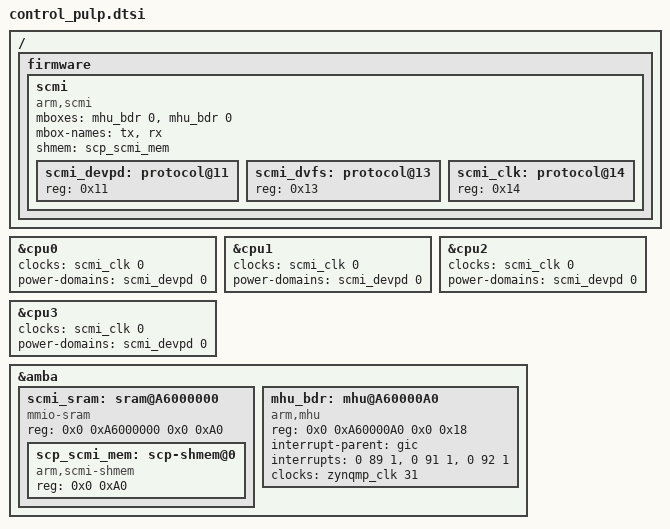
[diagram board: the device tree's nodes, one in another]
/ { //space after / is needed
    firmware{
        scmi {
            compatible ="arm,scmi";
            mboxes = <&mhu_bdr 0 &mhu_bdr 0>; 
            mbox-names = "tx","rx";
            shmem = <&scp_scmi_mem>;
            #address-cells = <1>;
            #size-cells = <0>; 

            
    		scmi_devpd: protocol@11 {
		    	reg = <0x11>;
		    	#power-domain-cells = <1>;
	    	};


            scmi_dvfs: protocol@13 {
			    reg = <0x13>;
			    #clock-cells = <1>;
		    };

            scmi_clk: protocol@14 {
			    reg = <0x14>;
			    #clock-cells = <1>;
	    	};

            // scmi_reset: protocol@16 {
			//     reg = <0x16>;
			//     #reset-cells = <1>;
	    	// };
            
            // scmi_volt: protocol@17 {
			//     reg = <0x17>;
			//     #clock-cells = <1>;
	    	// };
            
        };
    };

};//root node has to stay here (if amba is included in this node -> syntax error)

&cpu0 {
	clocks = <&scmi_clk 0>;
    power-domains = <&scmi_devpd 0>;
};

&cpu1 {
	clocks = <&scmi_clk 0>;
    power-domains = <&scmi_devpd 0>;
};

&cpu2 {
	clocks = <&scmi_clk 0>;
    power-domains = <&scmi_devpd 0>;
};

&cpu3 {
	clocks = <&scmi_clk 0>;
	power-domains = <&scmi_devpd 0>;
};

&amba{
    scmi_sram: sram@A6000000{
        compatible = "mmio-sram";
        reg = <0x0 0xA6000000 0x0 0xA0>; 
        #address-cells = <1>;
        #size-cells = <1>;
        ranges = <0 0x0 0xA6000000 0xA0>; 

        scp_scmi_mem: scp-shmem@0{
            compatible = "arm,scmi-shmem";
            reg = <0x0 0xA0>;
        };
    }; 

    mhu_bdr: mhu@A60000A0{ 
        #mbox-cells = <1>;
        compatible = "arm,mhu", "arm,primecell";
        clock-names = "clk_apb"; 
        reg = <0x0 0xA60000A0 0x0 0x18>;
        interrupt-parent = <&gic>; 
        interrupts =    <0 89 1>,
                        <0 91 1>,
                        <0 92 1>;
        interrupt-names = "mhu_bdr";
        clocks = <&zynqmp_clk 31>;
    };
}; 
